# N32MC47x_DP47x register map
Vendor: Nsingtech Ltd.; File version: 1.0
Registers are 32-bit, read-write, reset 0x0 unless marked. A register's access mark holds for its fields unless they carry their own. Offsets are from the block's base; [hi:lo] are bit positions; {n}, {i} and the like mark numbered series; 'fields as' and 'values as' point back to an identical list.

## HCU — Hardware Convolution Unit
Base 0x40025000
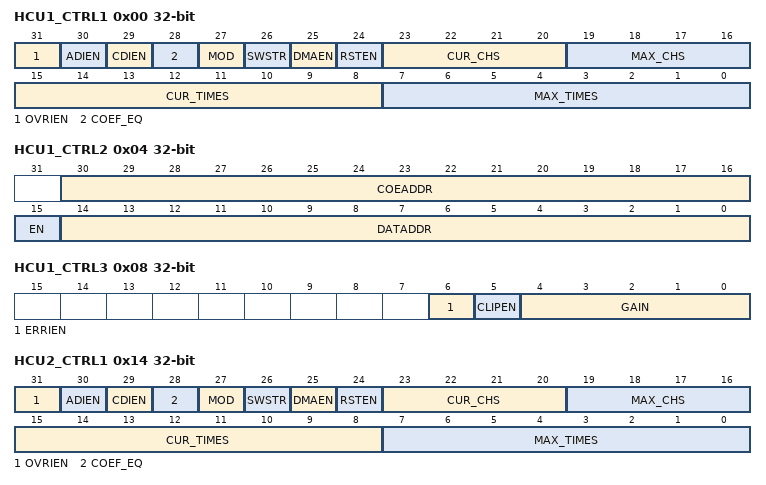
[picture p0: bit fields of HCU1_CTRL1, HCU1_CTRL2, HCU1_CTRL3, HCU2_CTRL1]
0x00 HCU1_CTRL1 — HCU1 Control Register 1
  [31] OVRIEN — Overflow interrupt enable
  [30] ADIEN — All channels calculation done interrupt enable
  [29] CDIEN — Single channel calculation done interrupt enable
  [28] COEF_EQ — Coefficient mode: 0=Different per channel, 1=Same for all
  [27] MOD — Work mode: 0=Hardware (ADC triggers), 1=Software
  [26] SWSTR — Software start trigger (software mode)
  [25] DMAEN — Internal DMA enable for result transfer
  [24] RSTEN — Soft reset, self-clearing (reads back 0)
  [23:20] CUR_CHS — Current conversion channel (software mode only)
  [19:16] MAX_CHS — Max conversion channels minus 1 (0xF=16 channels)
  [15:8] CUR_TIMES — Current sample round count (software mode only)
  [7:0] MAX_TIMES — Max sample rounds minus 1 (0xFF=256 rounds)
0x04 HCU1_CTRL2 — HCU1 Control Register 2 — Data and Coefficient Base Address
  [30:16] COEADDR — Coefficient base address in CCM SRAM (word-aligned, bit0=0)
  [15] EN — HCU filter enable: 0=Disable, 1=Enable
  [14:0] DATADDR — Sample data base address in CCM SRAM (word-aligned, bit0=0)
0x08 HCU1_CTRL3 — HCU1 Control Register 3 — Gain, Clip and Bus Error Interrupt
  [6] ERRIEN — Bus error interrupt enable
  [5] CLIPEN — Overflow clip: 1=Clip to 0x80000000/0x7FFFFFFF on overflow
  [4:0] GAIN — Output right-shift gain (0~16)
0x0C HCU1_CTRL4 — HCU1 Control Register 4 — DMA Destination Address in System SRAM
  [31:0] DSTADDR — DMA destination address in system SRAM for HCU result storage
0x10 HCU1_DAT ro — HCU1 Data Register — Latest Calculation Result (read-only)
  [31:0] DAT — 32-bit calculation result, hardware-updated after each HCU calculation
0x14 HCU2_CTRL1 — HCU2 Control Register 1
  fields as HCU1_CTRL1
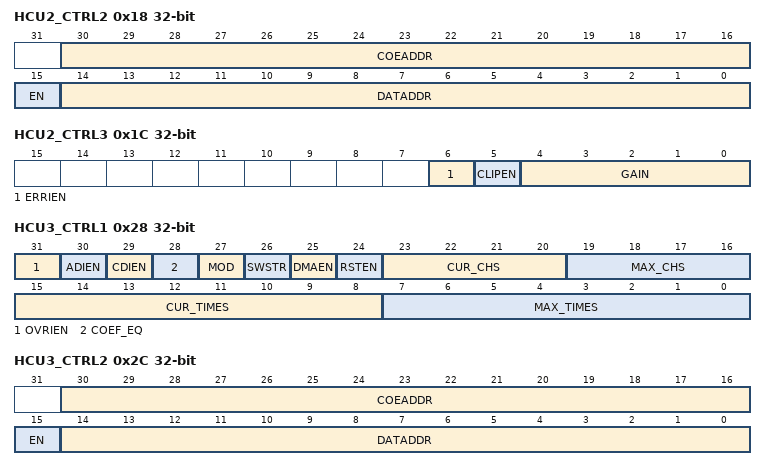
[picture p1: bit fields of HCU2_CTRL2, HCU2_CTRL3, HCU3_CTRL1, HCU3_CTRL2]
0x18 HCU2_CTRL2 — HCU2 Control Register 2 — Data and Coefficient Base Address
  fields as HCU1_CTRL2
0x1C HCU2_CTRL3 — HCU2 Control Register 3 — Gain, Clip and Bus Error Interrupt
  fields as HCU1_CTRL3
0x20 HCU2_CTRL4 — HCU2 Control Register 4 — DMA Destination Address in System SRAM
  fields as HCU1_CTRL4
0x24 HCU2_DAT ro — HCU2 Data Register — Latest Calculation Result (read-only)
  fields as HCU1_DAT
0x28 HCU3_CTRL1 — HCU3 Control Register 1
  fields as HCU1_CTRL1
0x2C HCU3_CTRL2 — HCU3 Control Register 2 — Data and Coefficient Base Address
  fields as HCU1_CTRL2
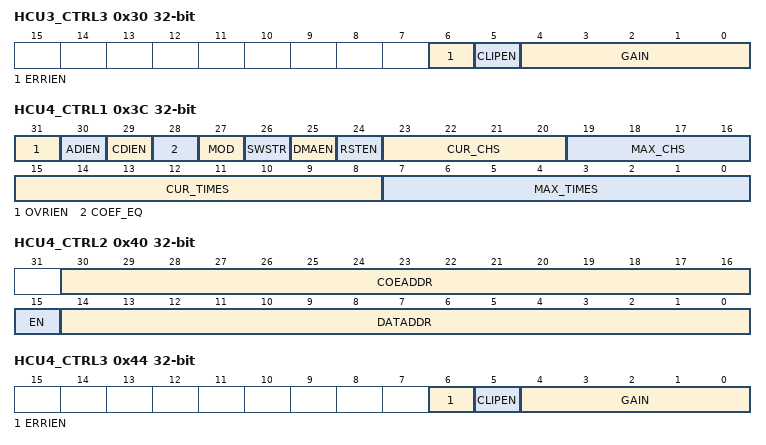
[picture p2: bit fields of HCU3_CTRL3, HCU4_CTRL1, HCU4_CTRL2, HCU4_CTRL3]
0x30 HCU3_CTRL3 — HCU3 Control Register 3 — Gain, Clip and Bus Error Interrupt
  fields as HCU1_CTRL3
0x34 HCU3_CTRL4 — HCU3 Control Register 4 — DMA Destination Address in System SRAM
  fields as HCU1_CTRL4
0x38 HCU3_DAT ro — HCU3 Data Register — Latest Calculation Result (read-only)
  fields as HCU1_DAT
0x3C HCU4_CTRL1 — HCU4 Control Register 1
  fields as HCU1_CTRL1
0x40 HCU4_CTRL2 — HCU4 Control Register 2 — Data and Coefficient Base Address
  fields as HCU1_CTRL2
0x44 HCU4_CTRL3 — HCU4 Control Register 3 — Gain, Clip and Bus Error Interrupt
  fields as HCU1_CTRL3
0x48 HCU4_CTRL4 — HCU4 Control Register 4 — DMA Destination Address in System SRAM
  fields as HCU1_CTRL4
0x4C HCU4_DAT ro — HCU4 Data Register — Latest Calculation Result (read-only)
  fields as HCU1_DAT
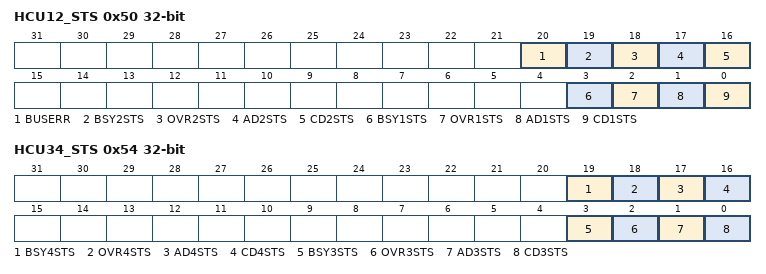
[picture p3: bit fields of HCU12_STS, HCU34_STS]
0x50 HCU12_STS — HCU1 and HCU2 Shared Status Register
  [20] BUSERR ro — Bus error flag — set when any HCU encounters a bus error
  [19] BSY2STS ro — HCU2 busy status (read-only)
  [18] OVR2STS ro — HCU2 overflow flag (rc_w0: write 0 to clear)
  [17] AD2STS ro — HCU2 all channels done (rc_w0: write 0 to clear)
  [16] CD2STS ro — HCU2 single calculation done (rc_w0: write 0 to clear)
  [3] BSY1STS ro — HCU1 busy status (read-only)
  [2] OVR1STS ro — HCU1 overflow flag (rc_w0: write 0 to clear)
  [1] AD1STS ro — HCU1 all channels done (rc_w0: write 0 to clear)
  [0] CD1STS ro — HCU1 single calculation done (rc_w0: write 0 to clear)
0x54 HCU34_STS — HCU3 and HCU4 Shared Status Register
  [19] BSY4STS ro — HCU4 busy status (read-only)
  [18] OVR4STS ro — HCU4 overflow flag (rc_w0: write 0 to clear)
  [17] AD4STS ro — HCU4 all channels done (rc_w0: write 0 to clear)
  [16] CD4STS ro — HCU4 single calculation done (rc_w0: write 0 to clear)
  [3] BSY3STS ro — HCU3 busy status (read-only)
  [2] OVR3STS ro — HCU3 overflow flag (rc_w0: write 0 to clear)
  [1] AD3STS ro — HCU3 all channels done (rc_w0: write 0 to clear)
  [0] CD3STS ro — HCU3 single calculation done (rc_w0: write 0 to clear)
{0x54+4i} HCU{i}_DIFFEN (i=1..4) — HCU{i} Differential Enable Register — bit[y]=1 enables first-level diff (K1) for CHy
  [15:0] DIFFEN — Per-channel diff enable, bit[y]=1 enables K1 usage for CHy
{0x64+4i} HCU{i}_DIFFCFG1 (i=1..4) — HCU{i} Differential Config 1 — bit[y]=1 enables DIFFCFG1 option for CHy
  [15:0] DIFFCFG1 — Per-channel diff config 1. Combined with DIFFCFG2/DIFFEN to select diff output
{0x74+4i} HCU{i}_DIFFCFG2 (i=1..4) — HCU{i} Differential Config 2 — bit[y]=1 enables DIFFCFG2 option for CHy
  [15:0] DIFFCFG2 — Per-channel diff config 2. Combined with DIFFCFG1/DIFFEN to select diff output
{0x44+0x44*i} HCU{i}_K1 (i=1..4) — HCU{i} First-Level Differential Coefficient K1
  [31:0] K1 — First-level diff coefficient. SW writes initial value before enable. After each calc, HW auto-updates with latest result for next channel
0x8C HCU1_CH0K2 — HCU1 Channel 0 Second-Level Differential Coefficient K2
  [31:0] CHK2 — Second-level diff coefficient for channel 0. SW writes init value; after 1st round updated by DMA from SRAM
{0x8C+4i} HCU1_CH{i}K2 (i=1..15) — HCU1 Channel {i} Second-Level Differential Coefficient K2
  [31:0] CHK2 — Second-level diff coefficient for channel {i}
{0xD0+4i} HCU2_CH{i}K2 (i=0..15) — HCU2 Channel {i} Second-Level Differential Coefficient K2
  [31:0] CHK2 — Second-level diff coefficient for channel {i}
{0x114+4i} HCU3_CH{i}K2 (i=0..15) — HCU3 Channel {i} Second-Level Differential Coefficient K2
  [31:0] CHK2 — Second-level diff coefficient for channel {i}
{0x158+4i} HCU4_CH{i}K2 (i=0..15) — HCU4 Channel {i} Second-Level Differential Coefficient K2
  [31:0] CHK2 — Second-level diff coefficient for channel {i}
